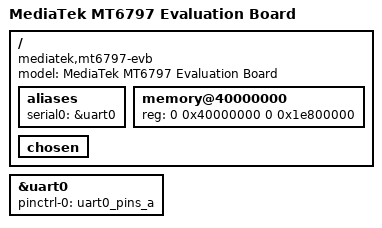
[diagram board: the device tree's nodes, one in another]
// SPDX-License-Identifier: GPL-2.0-only
/*
 * Copyright (c) 2017 MediaTek Inc.
 * Author: Mars.C <mars.cheng@mediatek.com>
 */

/dts-v1/;
#include "mt6797.dtsi"

/ {
	model = "MediaTek MT6797 Evaluation Board";
	compatible = "mediatek,mt6797-evb", "mediatek,mt6797";

	aliases {
		serial0 = &uart0;
	};

	memory@40000000 {
		device_type = "memory";
		reg = <0 0x40000000 0 0x1e800000>;
	};

	chosen {};
};

&uart0 {
	status = "okay";
	pinctrl-names = "default";
	pinctrl-0 = <&uart0_pins_a>;
};
